# renode register map
Vendor: litex
Registers are 32-bit, read-write, reset 0x0 unless marked. A register's access mark holds for its fields unless they carry their own. Offsets are from the block's base; [hi:lo] are bit positions.

## UART
Base 0xF0004000
Same registers: CONSOLE 0xF0006000, APP_UART 0xF0008000
0x00 RXTX
  [7:0] rxtx
0x04 TXFULL
  [0] txfull
0x08 RXEMPTY
  [0] rxempty
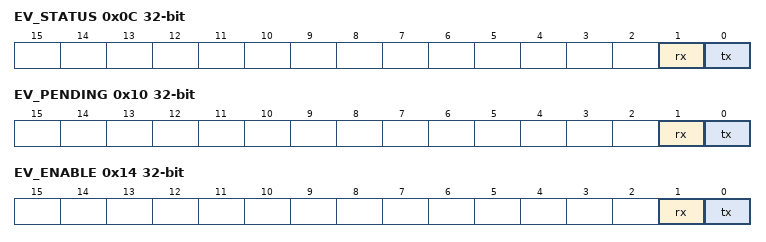
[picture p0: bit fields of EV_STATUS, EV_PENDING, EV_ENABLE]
0x0C EV_STATUS — This register contains the current raw level of the rx event trigger. Writes to this register have no effect.
  [1] rx — Level of the ``rx`` event
  [0] tx — Level of the ``tx`` event
0x10 EV_PENDING — When a rx event occurs, the corresponding bit will be set in this register. To clear the Event, set the corresponding bit in this register.
  [1] rx — `1` if a `rx` event occurred. This Event is triggered on a **falling** edge.
  [0] tx — `1` if a `tx` event occurred. This Event is triggered on a **falling** edge.
0x14 EV_ENABLE — This register enables the corresponding rx events. Write a ``0`` to this register to disable individual events.
  [1] rx — Write a ``1`` to enable the ``rx`` Event
  [0] tx — Write a ``1`` to enable the ``tx`` Event
0x18 TXEMPTY
  [0] txempty
0x1C RXFULL
  [0] rxfull

## INFO
Base 0xF0009000
0x00 DNA_ID1 — Bits 32-56 of `INFO_DNA_ID`.
  [31:0] dna_id
0x04 DNA_ID0 — Bits 0-31 of `INFO_DNA_ID`.
  [31:0] dna_id
0x08 GIT_MAJOR — Major git tag version. For example, this firmware was built from git tag ``v0.8.0``, so this value is ``0``.
  [7:0] git_major
0x0C GIT_MINOR reset 0x8 — Minor git tag version. For example, this firmware was built from git tag ``v0.8.0``, so this value is ``8``.
  [7:0] git_minor
0x10 GIT_REVISION — Revision git tag version. For example, this firmware was built from git tag ``v0.8.0``, so this value is ``0``.
  [7:0] git_revision
0x14 GIT_GITREV reset 0x933D6807 — First 32-bits of the git revision. This documentation was built from git rev ``933d6807``, so this value is 2470275079, which should be enough to check out the exact git version used to build this firmware.
0x18 GIT_GITEXTRA reset 0x4 — The number of additional commits beyond the git tag. For example, if this value is ``1``, then the repository this was built from has one additional commit beyond the tag indicated in `MAJOR`, `MINOR`, and `REVISION`.
  [9:0] git_gitextra
0x1C GIT_DIRTY reset 0x1
  [0] dirty — Set to ``1`` if this device was built from a git repo with uncommitted modifications.
0x20 PLATFORM_PLATFORM1 — Bits 32-63 of `INFO_PLATFORM_PLATFORM`.
  [31:0] platform_platform
0x24 PLATFORM_PLATFORM0 — Bits 0-31 of `INFO_PLATFORM_PLATFORM`.
  [31:0] platform_platform
0x28 PLATFORM_TARGET1 — Bits 32-63 of `INFO_PLATFORM_TARGET`.
  [31:0] platform_target
0x2C PLATFORM_TARGET0 — Bits 0-31 of `INFO_PLATFORM_TARGET`.
  [31:0] platform_target

## SRAM_EXT
Base 0xF000A000
0x00 CONFIG_STATUS
  [31:0] mode — The current configuration mode of the SRAM
0x04 READ_CONFIG
  [0] trigger — Writing to this bit triggers the SRAM mode status read update

## MEMLCD
Base 0xF000B000
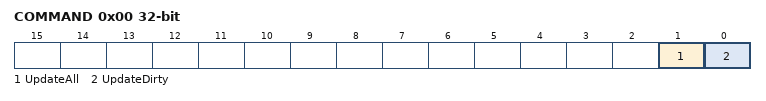
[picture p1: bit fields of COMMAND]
0x00 COMMAND
  [1] UpdateAll — Update full screen regardless of tag state
  [0] UpdateDirty — Write a ``1`` to flush dirty lines to the LCD
0x04 BUSY — A ``1`` indicates that the block is currently updating the LCD
  [0] busy
0x08 PRESCALER reset 0x63 — Prescaler value. LCD clock is module ``(clock / (prescaler+1))``. Reset value: ``99``, so for a default sysclk of 100MHz this yields an LCD ``SCLK`` of 1MHz
  [7:0] prescaler
0x0C EV_STATUS — This register contains the current raw level of the done event trigger. Writes to this register have no effect.
  [0] done — Level of the ``done`` event
0x10 EV_PENDING — When a done event occurs, the corresponding bit will be set in this register. To clear the Event, set the corresponding bit in this register.
  [0] done — `1` if a `done` event occurred. This Event is triggered on a **falling** edge.
0x14 EV_ENABLE — This register enables the corresponding done events. Write a ``0`` to this register to disable individual events.
  [0] done — Write a ``1`` to enable the ``done`` Event
